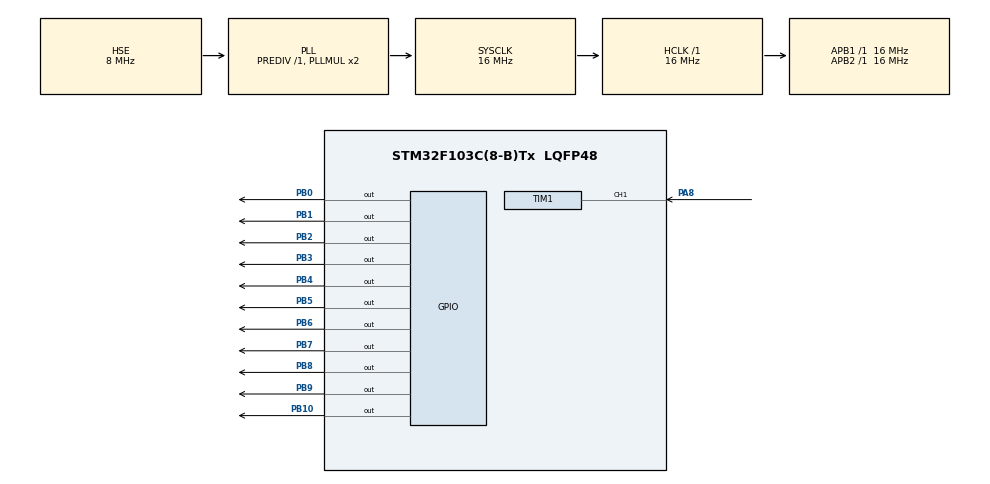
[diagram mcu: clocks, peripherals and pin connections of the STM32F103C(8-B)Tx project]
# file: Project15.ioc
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Mcu.Family=STM32F1
Mcu.Name=STM32F103C(8-B)Tx
Mcu.Package=LQFP48
NVIC.PriorityGroup=NVIC_PRIORITYGROUP_4
PA8.Signal=S_TIM1_CH1
PB0.Signal=GPIO_Output
PB1.Signal=GPIO_Output
PB10.Signal=GPIO_Output
PB2.Signal=GPIO_Output
PB3.Signal=GPIO_Output
PB4.Signal=GPIO_Output
PB5.Signal=GPIO_Output
PB6.Signal=GPIO_Output
PB7.Signal=GPIO_Output
PB8.Signal=GPIO_Output
PB9.Signal=GPIO_Output
PD0-OSC_IN.Mode=HSE-External-Oscillator
PD0-OSC_IN.Signal=RCC_OSC_IN
PD1-OSC_OUT.Mode=HSE-External-Oscillator
PD1-OSC_OUT.Signal=RCC_OSC_OUT
ProjectManager.HeapSize=0x200
ProjectManager.StackSize=0x400
ProjectManager.TargetToolchain=STM32CubeIDE
RCC.AHBFreq_Value=16000000
RCC.APB1Freq_Value=16000000
RCC.APB1TimFreq_Value=16000000
RCC.APB2Freq_Value=16000000
RCC.APB2TimFreq_Value=16000000
RCC.HCLKFreq_Value=16000000
RCC.PLLSourceVirtual=RCC_PLLSOURCE_HSE
RCC.SYSCLKFreq_VALUE=16000000
RCC.SYSCLKSource=RCC_SYSCLKSOURCE_PLLCLK
RCC.USBFreq_Value=16000000
SH.S_TIM1_CH1.0=TIM1_CH1,TriggerSource_TI1FP1
TIM1.AutoReloadPreload=TIM_AUTORELOAD_PRELOAD_ENABLE
TIM1.Period=100
TIM1.Slave_TriggerFilter=7
VP_SYS_VS_ND.Mode=No_Debug
VP_TIM1_VS_ControllerModeClock.Mode=Clock Mode
board=custom

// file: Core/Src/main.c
/* USER CODE BEGIN Header */
/**
  ******************************************************************************
  * @file           : main.c
  * @brief          : Main program body
  ******************************************************************************
  * @attention
  *
  * Copyright (c) 2025 STMicroelectronics.
  * All rights reserved.
  *
  * This software is licensed under terms that can be found in the LICENSE file
  * in the root directory of this software component.
  * If no LICENSE file comes with this software, it is provided AS-IS.
  *
  ******************************************************************************
  */
/* USER CODE END Header */
#include "main.h"

/* USER CODE BEGIN Includes */
#include "lcd.h"
#include "stdio.h"
/* USER CODE END Includes */

TIM_HandleTypeDef htim1;

void SystemClock_Config(void);
static void MX_GPIO_Init(void);
static void MX_TIM1_Init(void);

int main(void)
{

  /* MCU Configuration--------------------------------------------------------*/

  /* Reset of all peripherals, Initializes the Flash interface and the Systick. */
  HAL_Init();

  /* Configure the system clock */
  SystemClock_Config();

  /* Initialize all configured peripherals */
  MX_GPIO_Init();
  MX_TIM1_Init();
  /* USER CODE BEGIN 2 */

  lcd_init();
  uint32_t pulses = 0;
  __HAL_TIM_SET_COUNTER(&htim1, 0);
  HAL_TIM_Base_Start(&htim1);

  char str[16];

  /* USER CODE END 2 */

  /* Infinite loop */
  while (1)
  {

    /* USER CODE BEGIN 3 */

	  pulses = __HAL_TIM_GetCounter(&htim1);

	  sprintf(str, "Pulses: %d", pulses);

	  lcd_gotoxy(0, 0);
	  lcd_puts(str);
  }
  /* USER CODE END 3 */
}

void SystemClock_Config(void)
{
  RCC_OscInitTypeDef RCC_OscInitStruct = {0};
  RCC_ClkInitTypeDef RCC_ClkInitStruct = {0};

  /** Initializes the RCC Oscillators according to the specified parameters
  * in the RCC_OscInitTypeDef structure.
  */
  RCC_OscInitStruct.OscillatorType = RCC_OSCILLATORTYPE_HSE;
  RCC_OscInitStruct.HSEState = RCC_HSE_ON;
  RCC_OscInitStruct.HSEPredivValue = RCC_HSE_PREDIV_DIV1;
  RCC_OscInitStruct.HSIState = RCC_HSI_ON;
  RCC_OscInitStruct.PLL.PLLState = RCC_PLL_ON;
  RCC_OscInitStruct.PLL.PLLSource = RCC_PLLSOURCE_HSE;
  RCC_OscInitStruct.PLL.PLLMUL = RCC_PLL_MUL2;
  if (HAL_RCC_OscConfig(&RCC_OscInitStruct) != HAL_OK)
  {
    Error_Handler();
  }

  /** Initializes the CPU, AHB and APB buses clocks
  */
  RCC_ClkInitStruct.ClockType = RCC_CLOCKTYPE_HCLK|RCC_CLOCKTYPE_SYSCLK
                              |RCC_CLOCKTYPE_PCLK1|RCC_CLOCKTYPE_PCLK2;
  RCC_ClkInitStruct.SYSCLKSource = RCC_SYSCLKSOURCE_PLLCLK;
  RCC_ClkInitStruct.AHBCLKDivider = RCC_SYSCLK_DIV1;
  RCC_ClkInitStruct.APB1CLKDivider = RCC_HCLK_DIV1;
  RCC_ClkInitStruct.APB2CLKDivider = RCC_HCLK_DIV1;

  if (HAL_RCC_ClockConfig(&RCC_ClkInitStruct, FLASH_LATENCY_0) != HAL_OK)
  {
    Error_Handler();
  }
}

static void MX_TIM1_Init(void)
{

  TIM_SlaveConfigTypeDef sSlaveConfig = {0};
  TIM_MasterConfigTypeDef sMasterConfig = {0};

  htim1.Instance = TIM1;
  htim1.Init.Prescaler = 0;
  htim1.Init.CounterMode = TIM_COUNTERMODE_UP;
  htim1.Init.Period = 100;
  htim1.Init.ClockDivision = TIM_CLOCKDIVISION_DIV1;
  htim1.Init.RepetitionCounter = 0;
  htim1.Init.AutoReloadPreload = TIM_AUTORELOAD_PRELOAD_ENABLE;
  if (HAL_TIM_Base_Init(&htim1) != HAL_OK)
  {
    Error_Handler();
  }
  sSlaveConfig.SlaveMode = TIM_SLAVEMODE_EXTERNAL1;
  sSlaveConfig.InputTrigger = TIM_TS_TI1FP1;
  sSlaveConfig.TriggerPolarity = TIM_TRIGGERPOLARITY_RISING;
  sSlaveConfig.TriggerFilter = 7;
  if (HAL_TIM_SlaveConfigSynchro(&htim1, &sSlaveConfig) != HAL_OK)
  {
    Error_Handler();
  }
  sMasterConfig.MasterOutputTrigger = TIM_TRGO_RESET;
  sMasterConfig.MasterSlaveMode = TIM_MASTERSLAVEMODE_DISABLE;
  if (HAL_TIMEx_MasterConfigSynchronization(&htim1, &sMasterConfig) != HAL_OK)
  {
    Error_Handler();
  }

}

static void MX_GPIO_Init(void)
{
  GPIO_InitTypeDef GPIO_InitStruct = {0};

  /* GPIO Ports Clock Enable */
  __HAL_RCC_GPIOD_CLK_ENABLE();
  __HAL_RCC_GPIOB_CLK_ENABLE();
  __HAL_RCC_GPIOA_CLK_ENABLE();

  /*Configure GPIO pin Output Level */
  HAL_GPIO_WritePin(GPIOB, GPIO_PIN_0|GPIO_PIN_1|GPIO_PIN_2|GPIO_PIN_10
                          |GPIO_PIN_3|GPIO_PIN_4|GPIO_PIN_5|GPIO_PIN_6
                          |GPIO_PIN_7|GPIO_PIN_8|GPIO_PIN_9, GPIO_PIN_RESET);

  /*Configure GPIO pins : PB0 PB1 PB2 PB10
                           PB3 PB4 PB5 PB6
                           PB7 PB8 PB9 */
  GPIO_InitStruct.Pin = GPIO_PIN_0|GPIO_PIN_1|GPIO_PIN_2|GPIO_PIN_10
                          |GPIO_PIN_3|GPIO_PIN_4|GPIO_PIN_5|GPIO_PIN_6
                          |GPIO_PIN_7|GPIO_PIN_8|GPIO_PIN_9;
  GPIO_InitStruct.Mode = GPIO_MODE_OUTPUT_PP;
  GPIO_InitStruct.Pull = GPIO_NOPULL;
  GPIO_InitStruct.Speed = GPIO_SPEED_FREQ_LOW;
  HAL_GPIO_Init(GPIOB, &GPIO_InitStruct);

}

void Error_Handler(void)
{
  __disable_irq();
  while (1)
  {
  }
}
